AUTOSAR XML (schema 4-2-2)
package /ComponentTypes
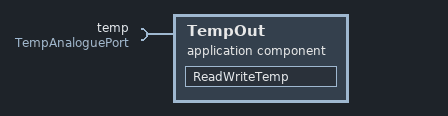
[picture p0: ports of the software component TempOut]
  application sw component type TempOut
    require port temp: required-com-specs=[{data-element=tempOut, init-value=0}, {data-element=tempIn, init-value=0}], required-interface=TempAnaloguePort
    behavior TempOut_InternalBehavior: data-type-mapping=tempMapSet
      data received event DRT_ReadTemp_temp_tempIn: start-on-event=ReadWriteTemp, data=temp.tempIn
      runnable ReadWriteTemp
        data-receive-point-by-arguments:
          access REC_temp_tempIn: accessed-variable=temp.tempIn
          access REC_temp_tempOut: accessed-variable=temp.tempOut
  swc implementation TempOut_Implementation: behavior=TempOut_InternalBehavior
